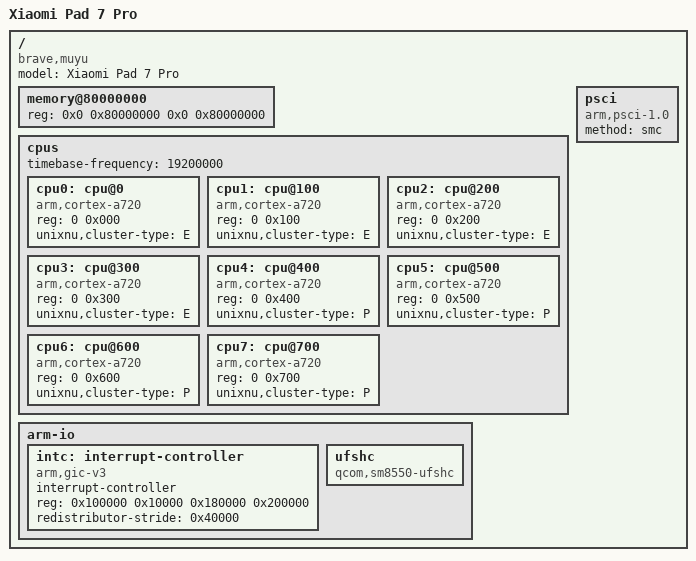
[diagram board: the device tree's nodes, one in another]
// SPDX-License-Identifier: BSD-3-Clause
// Xiaomi Pad 7 Pro (muyu, SM8635 cliffs): the hardware tree the common ADT generator turns into the
// Apple device tree.
//
// Every value here is the one the working iPadOS 17 image already declares, taken from
// scripts/make-muyu-adt.py (that board's ADT is a schema-1 build of the same numbers): DRAM at
// 0x80000000, 2 GiB as reported by the bootloader's SMEM table, 19.2 MHz timebase, the GIC inside the
// 0x17000000 APSS window, the QCOM UFS host controller as a matching anchor for ShengUfs.
//
// Only hardware belongs here. /chosen, /defaults, /product, /buttons, /pram, /memory-map and the rest
// come from the board's own [adt.*] tables; the generator prepends the OS identity's compatible.
/dts-v1/;

/ {
    compatible = "brave,muyu", "qcom,cliffsp";
    model = "Xiaomi Pad 7 Pro";
    #address-cells = <2>;
    #size-cells = <2>;

    // The DRAM window DarwinBoot hands to XNU. One contiguous range: the ADT hand-off requires it.
    memory@80000000 {
        device_type = "memory";
        reg = <0x0 0x80000000 0x0 0x80000000>;
    };

    cpus {
        #address-cells = <2>;
        #size-cells = <0>;
        timebase-frequency = <19200000>;
        // Eight Kryo cores, Affinity1 numbering 0x000..0x700. One compatibility string for every core:
        // AppleARMCPU rejects a tree whose CPU nodes do not share it ("CPU configuration in
        // device tree is invalid" @AppleARMCPU.cpp:111), which is what the 17 line's ADT and the
        // other iPadOS 27 board both do. The E/P split rides on unixnu,cluster-type instead.
        cpu0: cpu@0 { device_type = "cpu"; compatible = "arm,cortex-a720"; reg = <0 0x000>; };
        cpu1: cpu@100 { device_type = "cpu"; compatible = "arm,cortex-a720"; reg = <0 0x100>; };
        cpu2: cpu@200 { device_type = "cpu"; compatible = "arm,cortex-a720"; reg = <0 0x200>; };
        cpu3: cpu@300 { device_type = "cpu"; compatible = "arm,cortex-a720"; reg = <0 0x300>; };
        cpu4: cpu@400 { device_type = "cpu"; compatible = "arm,cortex-a720"; reg = <0 0x400>; };
        cpu5: cpu@500 { device_type = "cpu"; compatible = "arm,cortex-a720"; reg = <0 0x500>; };
        cpu6: cpu@600 { device_type = "cpu"; compatible = "arm,cortex-a720"; reg = <0 0x600>; };
        cpu7: cpu@700 { device_type = "cpu"; compatible = "arm,cortex-a720"; reg = <0 0x700>; };
    };

    psci {
        compatible = "arm,psci-1.0";
        method = "smc";
    };

    arm-io {
        device_type = "arm-io";
        #address-cells = <2>;
        #size-cells = <2>;
        // Child addresses are offsets inside this window; the GIC sits at 0x17100000.
        ranges = <0x0 0x0 0x0 0x17000000 0x0 0x08000000>;

        intc: interrupt-controller {
            compatible = "arm,gic-v3";
            #interrupt-cells = <3>;
            interrupt-controller;
            // distributor at 0x17100000, redistributors at 0x17180000 (offsets inside arm-io).
            reg = <0x100000 0x10000 0x180000 0x200000>;
            redistributor-stride = <0x40000>;
        };

        // The UFS controller lives at 0x1d84000, below this window, so it carries no reg: the node
        // exists for class matching only and ShengUfs takes its physical windows from GccUfs.h.
        ufshc {
            compatible = "qcom,sm8550-ufshc";
        };
    };
};

// AMP/Edge requires an explicit E/P type; a missing type becomes SMP and cluster_type_to_pset_type()
// rejects it during processor_bootstrap(). Four A520 cores, three A720 and one X4 (the split this SoC
// reports through the EPSS domains).
&cpu0 { unixnu,cluster-type = "E"; };
&cpu1 { unixnu,cluster-type = "E"; };
&cpu2 { unixnu,cluster-type = "E"; };
&cpu3 { unixnu,cluster-type = "E"; };
&cpu4 { unixnu,cluster-type = "P"; };
&cpu5 { unixnu,cluster-type = "P"; };
&cpu6 { unixnu,cluster-type = "P"; };
&cpu7 { unixnu,cluster-type = "P"; };
